# ATSAMC21N18A device description
Architecture: CORTEX-M0PLUS; Family: SAMC; Series: SAMC21
Registers are 32-bit, read-write, reset 0x0 unless marked. A register's access mark holds for its fields unless they carry their own. Offsets are from the block's base; [hi:lo] are bit positions; {n}, {i} and the like mark numbered series; 'fields as' and 'values as' point back to an identical list.

## MTB — Cortex-M0+ Micro-Trace Buffer
Instances: MTB 0x41008000
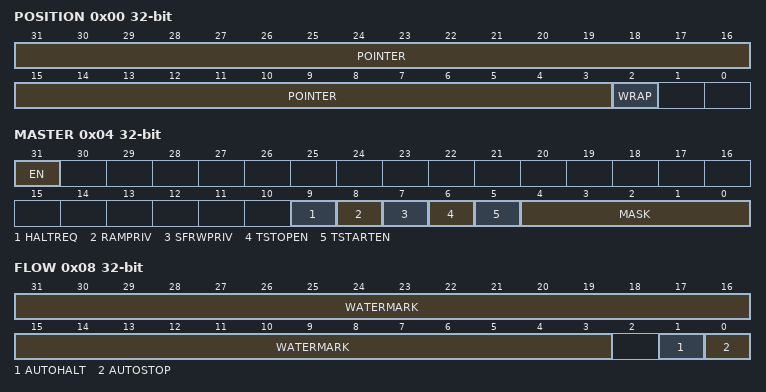
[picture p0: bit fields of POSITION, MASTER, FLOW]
0x00 POSITION reset not defined — MTB Position
  [31:3] POINTER — Trace Packet Location Pointer
  [2] WRAP — Pointer Value Wraps
0x04 MASTER — MTB Master
  [31] EN — Main Trace Enable
  [9] HALTREQ — Halt Request
  [8] RAMPRIV — SRAM Privilege
  [7] SFRWPRIV — Special Function Register Write Privilege
  [6] TSTOPEN — Trace Stop Input Enable
  [5] TSTARTEN — Trace Start Input Enable
  [4:0] MASK — Maximum Value of the Trace Buffer in SRAM
0x08 FLOW — MTB Flow
  [31:3] WATERMARK — Watermark value
  [1] AUTOHALT — Auto Halt Request
  [0] AUTOSTOP — Auto Stop Tracing
0x0C BASE ro reset not defined — MTB Base
0xF00 ITCTRL reset not defined — MTB Integration Mode Control
0xFA0 CLAIMSET reset not defined (atomic set) — MTB Claim Set
0xFA4 CLAIMCLR reset not defined (atomic clear) — MTB Claim Clear
0xFB0 LOCKACCESS reset not defined — MTB Lock Access
0xFB4 LOCKSTATUS ro reset not defined — MTB Lock Status
0xFB8 AUTHSTATUS ro reset not defined — MTB Authentication Status
0xFBC DEVARCH ro reset not defined — MTB Device Architecture
0xFC8 DEVID ro reset not defined — MTB Device Configuration
0xFCC DEVTYPE ro reset not defined — MTB Device Type
{0xFC0+4i} PID{i} ro reset not defined (i=4..7) — Peripheral Identification {i}
{0xFE0+4i} PID{i} ro reset not defined (i=0..3) — Peripheral Identification {i}
{0xFF0+4i} CID{i} ro reset not defined (i=0..3) — Component Identification {i}

## OTP3_FUSES — Non-Volatile Fuses
Instances: OTP3_FUSES 0x00806010 in fuses
0x04 OTP3_WORD_1 ro reset not defined — OTP3 Page Word 1
  [31] NVMCTRL_DUMMY2 — Dummy for OTP row 3

## OTP5_FUSES — Non-Volatile Fuses
Instances: OTP5_FUSES 0x00806020 in fuses
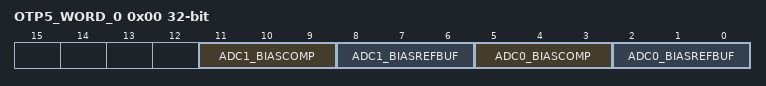
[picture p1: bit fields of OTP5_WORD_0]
0x00 OTP5_WORD_0 ro reset not defined — OTP5 Page Word 0
  [11:9] ADC1_BIASCOMP — ADC Comparator Scaling
  [8:6] ADC1_BIASREFBUF — ADC Bias Reference Buffer Scaling
  [5:3] ADC0_BIASCOMP — ADC Comparator Scaling
  [2:0] ADC0_BIASREFBUF — ADC Bias Reference Buffer Scaling

## TEMP_LOG_FUSES — Non-Volatile Fuses
Instances: TEMP_LOG_FUSES 0x00806030 in fuses
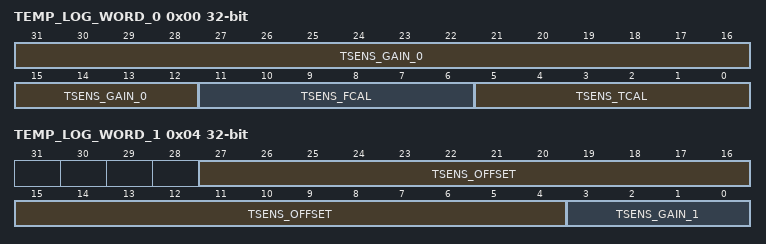
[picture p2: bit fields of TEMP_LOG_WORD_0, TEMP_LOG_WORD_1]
0x00 TEMP_LOG_WORD_0 ro reset not defined — TEMP_LOG Page Word 0
  [31:12] TSENS_GAIN_0 — Gain Calibration bits 19:0
  [11:6] TSENS_FCAL — Frequency Calibration
  [5:0] TSENS_TCAL — Temperature Calibration
0x04 TEMP_LOG_WORD_1 ro reset not defined — TEMP_LOG Page Word 1
  [27:4] TSENS_OFFSET — Offse Calibration
  [3:0] TSENS_GAIN_1 — Gain Calibration bits 23:20

## USER_FUSES — Non-Volatile Fuses
Instances: USER_FUSES 0x00804000 in fuses
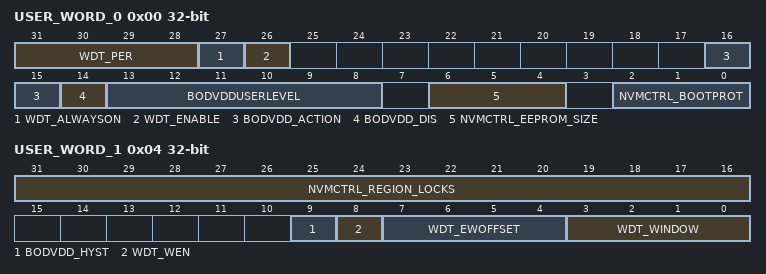
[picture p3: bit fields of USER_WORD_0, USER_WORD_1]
0x00 USER_WORD_0 reset not defined — USER Page Word 0
  [31:28] WDT_PER — WDT Period
    0=CYC8 (8 clock cycles); 1=CYC16 (16 clock cycles); 2=CYC32 (32 clock cycles); 3=CYC64 (64 clock cycles); 4=CYC128 (128 clock cycles); 5=CYC256 (256 clock cycles); 6=CYC512 (512 clock cycles); 7=CYC1024 (1024 clock cycles); 8=CYC2048 (2048 clock cycles); 9=CYC4096 (4096 clock cycles); 10=CYC8192 (8192 clock cycles); 11=CYC16384 (16384 clock cycles)
  [27] WDT_ALWAYSON
    0=DISABLED (WDT is enabled and disabled through ENABLE bit); 1=ENABLED (WDT is enabled and can only be disabled by a power-on reset)
  [26] WDT_ENABLE
    0=DISABLED (WDT is disabled); 1=ENABLED (WDT is enabled)
  [16:15] BODVDD_ACTION
    0=NONE (No action); 1=RESET (The BODVDD generates a reset); 2=INT (The BODVDD generates an interrupt)
  [14] BODVDD_DIS — BODVDD Disable
    0=DISABLED (BODVDD is disabled); 1=ENABLED (BODVDD is enabled)
  [13:8] BODVDDUSERLEVEL
  [6:4] NVMCTRL_EEPROM_SIZE — EEPROM Size
    7=SIZE_0BYTES (0 Bytes); 6=SIZE_256BYTES (256 Bytes); 5=SIZE_512BYTES (512 Bytes); 4=SIZE_1024BYTES (1024 Bytes); 3=SIZE_2048BYTES (2048 Bytes); 2=SIZE_4096BYTES (4096 Bytes); 1=SIZE_8192BYTES (8192 Bytes); 0=SIZE_16384BYTES (16384 Bytes)
  [2:0] NVMCTRL_BOOTPROT — Bootloader Size
    7=SIZE_0BYTES (0 Bytes); 6=SIZE_512BYTES (512 Bytes); 5=SIZE_1024BYTES (1024 Bytes); 4=SIZE_2048BYTES (2048 Bytes); 3=SIZE_4096BYTES (4096 Bytes); 2=SIZE_8192BYTES (8192 Bytes); 1=SIZE_16384BYTES (16384 Bytes); 0=SIZE_32768BYTES (32768 Bytes)
0x04 USER_WORD_1 reset not defined — USER Page Word 1
  [31:16] NVMCTRL_REGION_LOCKS — NVM Region Locks
  [9] BODVDD_HYST — BODVDD Hysterisis
    0=DISABLED (No Hysteresis); 1=ENABLED (Hysteresis Enabled)
  [8] WDT_WEN — WDT Window Mode Enable
    0=DISABLED (WDT is disabled); 1=ENABLED (WDT is enabled)
  [7:4] WDT_EWOFFSET — WDT Early Warning Offset
    values as USER_WORD_0.WDT_PER
  [3:0] WDT_WINDOW
    values as USER_WORD_0.WDT_PER
